# f2838x_cm_cm_i2c_regs register map
Vendor: Texas Instruments
Peripheral module from a debugger description file (folder C2000).
Address unit: 16 bits
Registers are 32-bit, read-write, no defined reset value unless marked. A register's access mark holds for its fields unless they carry their own. Offsets are as the file gives them; lines under a group give offsets from that group; [hi:lo] are bit positions; {n}, {i} and the like mark numbered series; 'fields as' and 'values as' point back to an identical list; <NAME> marks a mode.

## CM_I2C_REGS — CM I2C Registers
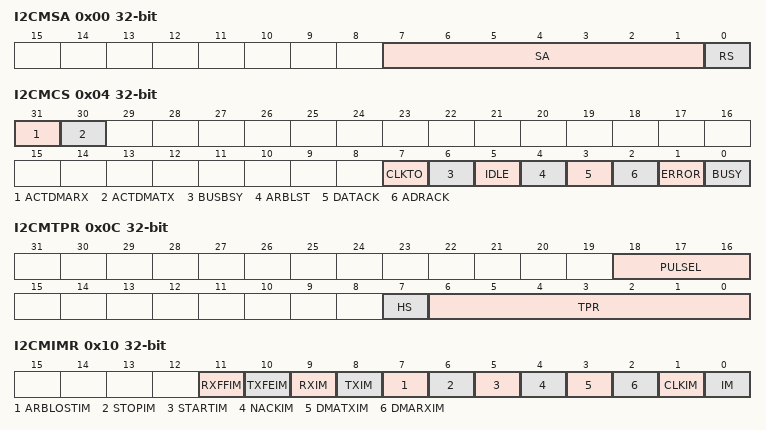
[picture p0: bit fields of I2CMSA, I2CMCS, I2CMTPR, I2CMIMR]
0x00 I2CMSA — I2C Master Slave Address
  [7:1] SA — I2C Slave Address
  [0] RS — Receive/Send
0x04 I2CMCS ro — I2C Master Control/Status
  [31] ACTDMARX — DMA RX Active Status
  [30] ACTDMATX — DMA TX Active Status
  [7] CLKTO — Clock Timeout Error
  [6] BUSBSY — Bus Busy
  [5] IDLE — I2C Idle
  [4] ARBLST — Arbitration Lost
  [3] DATACK — Acknowledge Data
  [2] ADRACK — Acknowledge Address
  [1] ERROR
  [0] BUSY — I2C Busy
0x08 I2CMDR — I2C Master Data
  [7:0] DATA — Data transmitted/received
0x0C I2CMTPR — I2C Master Timer Period
  [18:16] PULSEL — Glitch Suppression Pulse Width
  [7] HS — High-Speed Enable
  [6:0] TPR — Timer Period
0x10 I2CMIMR — I2C Master Interrupt Mask
  [11] RXFFIM — Receive FIFO Full Interrupt Mask
  [10] TXFEIM — Transmit FIFO Empty Interrupt Mask
  [9] RXIM — Receive FIFO Request Interrupt Mask
  [8] TXIM — Transmit FIFO Request Interrupt Mask
  [7] ARBLOSTIM — Arbitration Lost Interrupt Mask
  [6] STOPIM — STOP Detection Interrupt Mask
  [5] STARTIM — START Detection Interrupt Mask
  [4] NACKIM — Address/Data NACK Interrupt Mask
  [3] DMATXIM — Transmit DMA Interrupt Mask
  [2] DMARXIM — Receive DMA Interrupt Mask
  [1] CLKIM — Clock Timeout Interrupt Mask
  [0] IM — Master Interrupt Mask
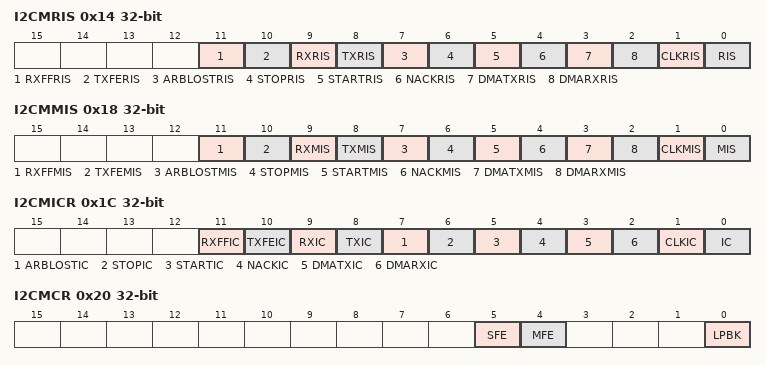
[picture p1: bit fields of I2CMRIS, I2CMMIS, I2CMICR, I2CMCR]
0x14 I2CMRIS ro — I2C Master Raw Interrupt Status
  [11] RXFFRIS — Receive FIFO Full Raw Interrupt Status
  [10] TXFERIS — Transmit FIFO Empty Raw Interrupt Status
  [9] RXRIS — Receive FIFO Request Raw Interrupt Status
  [8] TXRIS — Transmit Request Raw Interrupt Status
  [7] ARBLOSTRIS — Arbitration Lost Raw Interrupt Status
  [6] STOPRIS — STOP Detection Raw Interrupt Status
  [5] STARTRIS — START Detection Raw Interrupt Status
  [4] NACKRIS — Address/Data NACK Raw Interrupt Status
  [3] DMATXRIS — Transmit DMA Raw Interrupt Status
  [2] DMARXRIS — Receive DMA Raw Interrupt Status
  [1] CLKRIS — Clock Timeout Raw Interrupt Status
  [0] RIS — Master Raw Interrupt Status
0x18 I2CMMIS ro — I2C Master Masked Interrupt Status
  [11] RXFFMIS — Receive FIFO Full Interrupt Mask
  [10] TXFEMIS — Transmit FIFO Empty Interrupt Mask
  [9] RXMIS — Receive FIFO Request Interrupt Mask
  [8] TXMIS — Transmit Request Interrupt Mask
  [7] ARBLOSTMIS — Arbitration Lost Interrupt Mask
  [6] STOPMIS — STOP Detection Interrupt Mask
  [5] STARTMIS — START Detection Interrupt Mask
  [4] NACKMIS — Address/Data NACK Interrupt Mask
  [3] DMATXMIS — Transmit DMA Interrupt Status
  [2] DMARXMIS — Receive DMA Interrupt Status
  [1] CLKMIS — Clock Timeout Masked Interrupt Status
  [0] MIS — Masked Interrupt Status
0x1C I2CMICR — I2C Master Interrupt Clear
  [11] RXFFIC — Receive FIFO Full Interrupt Clear
  [10] TXFEIC — Transmit FIFO Empty Interrupt Clear
  [9] RXIC — Receive FIFO Request Interrupt Clear
  [8] TXIC — Transmit FIFO Request Interrupt Clear
  [7] ARBLOSTIC — Arbitration Lost Interrupt Clear
  [6] STOPIC — STOP Detection Interrupt Clear
  [5] STARTIC — START Detection Interrupt Clear
  [4] NACKIC — Address/Data NACK Interrupt Clear
  [3] DMATXIC — Transmit DMA Interrupt Clear
  [2] DMARXIC — Receive DMA Interrupt Clear
  [1] CLKIC — Clock Timeout Interrupt Clear
  [0] IC — Master Interrupt Clear
0x20 I2CMCR — I2C Master Configuration
  [5] SFE — I2C Slave Function Enable
  [4] MFE — I2C Master Function Enable
  [0] LPBK — I2C Loopback
0x24 I2CMCLKOCNT — I2C Master Clock Low Timeout Count
  [7:0] CNTL — I2C Master Count
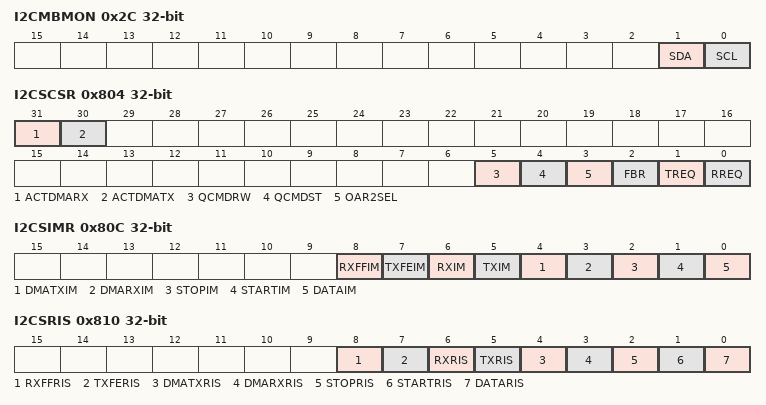
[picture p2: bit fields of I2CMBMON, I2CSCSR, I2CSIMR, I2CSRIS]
0x2C I2CMBMON ro — I2C Master Bus Monitor
  [1] SDA — I2C SDA Status
  [0] SCL — I2C SCL Status
0x30 I2CMBLEN — I2C Master Burst Length
  [7:0] CNTL — I2C Burst Length
0x34 I2CMBCNT ro — I2C Master Burst Count
  [7:0] CNTL
0x800 I2CSOAR — I2C Slave Own Address
  [6:0] OAR
0x804 I2CSCSR ro — I2C Slave Control/Status
  [31] ACTDMARX — DMA RX Active Status
  [30] ACTDMATX — DMA TX Active Status
  [5] QCMDRW — Quick Command Read / Write
  [4] QCMDST — Quick Command Status
  [3] OAR2SEL — OAR2 Address Matched
  [2] FBR — First Byte Received
  [1] TREQ — Transmit Request
  [0] RREQ — Receive Request
0x808 I2CSDR — I2C Slave Data
  [7:0] DATA — Data for Transfer
0x80C I2CSIMR — I2C Slave Interrupt Mask
  [8] RXFFIM — Receive FIFO Full Interrupt Mask
  [7] TXFEIM — Transmit FIFO Empty Interrupt Mask
  [6] RXIM — Receive FIFO Request Interrupt Mask
  [5] TXIM — Transmit FIFO Request Interrupt Mask
  [4] DMATXIM — Transmit DMA Interrupt Mask
  [3] DMARXIM — Receive DMA Interrupt Mask
  [2] STOPIM — Stop Condition Interrupt Mask
  [1] STARTIM — Start Condition Interrupt Mask
  [0] DATAIM — Data Interrupt Mask
0x810 I2CSRIS ro — I2C Slave Raw Interrupt Status
  [8] RXFFRIS — Receive FIFO Full Raw Interrupt Status
  [7] TXFERIS — Transmit FIFO Empty Raw Interrupt Status
  [6] RXRIS — Receive FIFO Request Raw Interrupt Status
  [5] TXRIS — Transmit Request Raw Interrupt Status
  [4] DMATXRIS — Transmit DMA Raw Interrupt Status
  [3] DMARXRIS — Receive DMA Raw Interrupt Status
  [2] STOPRIS — Stop Condition Raw Interrupt Status
  [1] STARTRIS — Start Condition Raw Interrupt Status
  [0] DATARIS — Data Raw Interrupt Status
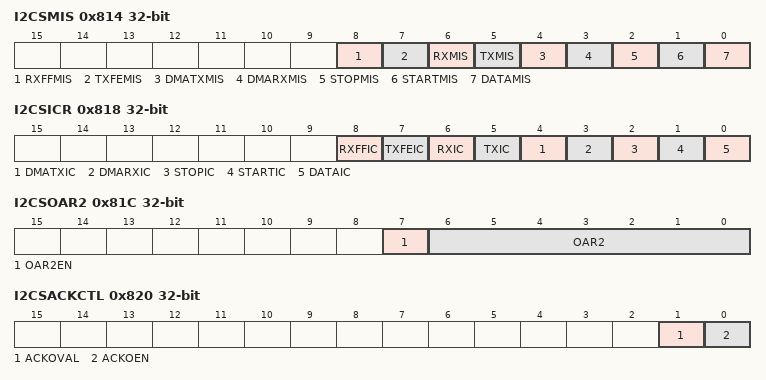
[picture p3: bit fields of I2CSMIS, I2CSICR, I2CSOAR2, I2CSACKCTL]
0x814 I2CSMIS ro — I2C Slave Masked Interrupt Status
  [8] RXFFMIS — Receive FIFO Full Interrupt Mask
  [7] TXFEMIS — Transmit FIFO Empty Interrupt Mask
  [6] RXMIS — Receive FIFO Request Interrupt Mask
  [5] TXMIS — Transmit FIFO Request Interrupt Mask
  [4] DMATXMIS — Transmit DMA Masked Interrupt Status
  [3] DMARXMIS — Receive DMA Masked Interrupt Status
  [2] STOPMIS — Stop Condition Masked Interrupt Status
  [1] STARTMIS — Start Condition Masked Interrupt Status
  [0] DATAMIS — Data Masked Interrupt Status
0x818 I2CSICR — I2C Slave Interrupt Clear
  [8] RXFFIC — Receive FIFO Full Interrupt Mask
  [7] TXFEIC — Transmit FIFO Empty Interrupt Mask
  [6] RXIC — Receive Request Interrupt Mask
  [5] TXIC — Transmit Request Interrupt Mask
  [4] DMATXIC — Transmit DMA Interrupt Clear
  [3] DMARXIC — Receive DMA Interrupt Clear
  [2] STOPIC — Stop Condition Interrupt Clear
  [1] STARTIC — Start Condition Interrupt Clear
  [0] DATAIC — Data Interrupt Clear
0x81C I2CSOAR2 — I2C Slave Own Address 2
  [7] OAR2EN — I2C Slave Own Address 2 Enable
  [6:0] OAR2 — I2C Slave Own Address 2
0x820 I2CSACKCTL — I2C Slave ACK Control
  [1] ACKOVAL — I2C Slave ACK Override Value
  [0] ACKOEN — I2C Slave ACK Override Enable
0xF00 I2CFIFODATARX ro
  [7:0] DATA — I2C RX FIFO Read Data Byte
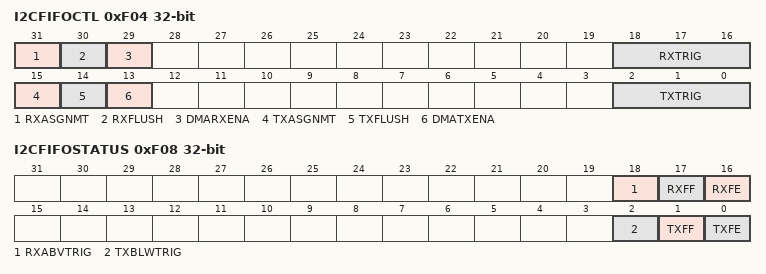
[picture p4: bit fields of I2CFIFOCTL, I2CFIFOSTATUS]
0xF04 I2CFIFOCTL — I2C FIFO Control
  [31] RXASGNMT — RX Control Assignment
  [30] RXFLUSH — RX FIFO Flush
  [29] DMARXENA — DMA RX Channel Enable
  [18:16] RXTRIG — RX FIFO Trigger
  [15] TXASGNMT — TX Control Assignment
  [14] TXFLUSH — TX FIFO Flush
  [13] DMATXENA — DMA TX Channel Enable
  [2:0] TXTRIG — TX FIFO Trigger
0xF08 I2CFIFOSTATUS ro
  [18] RXABVTRIG — RX FIFO Above Trigger Level
  [17] RXFF — RX FIFO Full
  [16] RXFE — RX FIFO Empty
  [2] TXBLWTRIG — TX FIFO Below Trigger Level
  [1] TXFF — TX FIFO Full
  [0] TXFE — TX FIFO Empty
0xFC0 I2CPP ro — I2C Peripheral Properties
  [0] HS — High-Speed Capable
0xFC4 I2CPC — I2C Peripheral Configuration
  [0] HS — High-Speed Capable
